# SF32LB55x register map
File version: 1.0
CPU: CM33 r0p1, little endian, MPU, FPU, 3 interrupt priority bits
Registers are 32-bit, read-write, reset 0x0 unless marked. A register's access mark holds for its fields unless they carry their own. Offsets are from the block's base; [hi:lo] are bit positions; {n}, {i} and the like mark numbered series.

## SDADC
Base 0x40057000
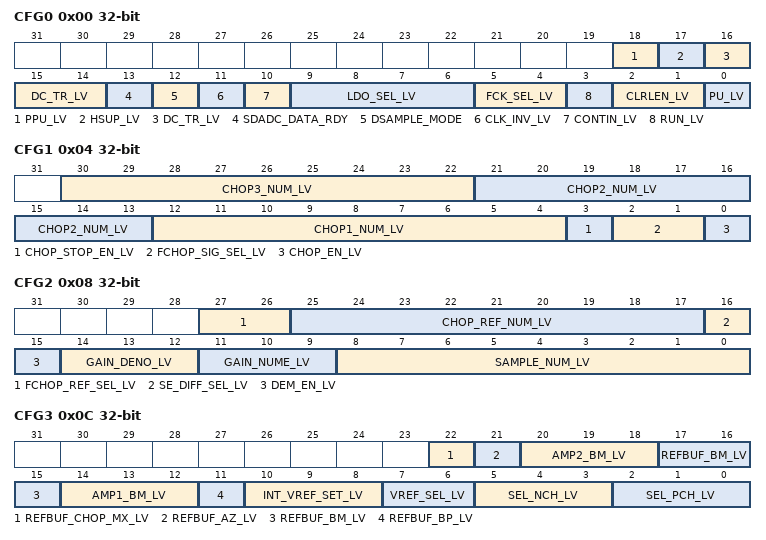
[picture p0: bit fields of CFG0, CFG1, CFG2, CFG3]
0x00 CFG0
  [18] PPU_LV — reference generate pre-power-up
  [17] HSUP_LV — supply votage 0x0:1.8v 0x1: 3.3v
  [16:14] DC_TR_LV — DCTR
  [13] SDADC_DATA_RDY — 1 indicates sample adc data done once
  [12] DSAMPLE_MODE — 1: sample adc data on a maximum of five channels in non-contious mode; 0: sample adc data on only one channel in non-contious mode
  [11] CLK_INV_LV — inverse clk to folter or not 0x0:no 0x1:yes
  [10] CONTIN_LV — continous sample or not 0x0:no 0x1:yes
  [9:6] LDO_SEL_LV — ldo voltage selection
  [5:4] FCK_SEL_LV — ADC clock dividing selection
  [3] RUN_LV — start sdadc sample in continous mode
  [2:1] CLRLEN_LV — length of clear pulse
  [0] PU_LV — power up
0x04 CFG1
  [30:22] CHOP3_NUM_LV — chopping weight controlling of 3rd stage
  [21:13] CHOP2_NUM_LV — chopping weight controlling of 2nd stage
  [12:4] CHOP1_NUM_LV — chopping weight controlling of 1st stage
  [3] CHOP_STOP_EN_LV — chopping weight controlling enable
  [2:1] FCHOP_SIG_SEL_LV — siganal path chopping frequency
  [0] CHOP_EN_LV — chopping enable
0x08 CFG2
  [27:26] FCHOP_REF_SEL_LV — reference buffer chopping frequency
  [25:17] CHOP_REF_NUM_LV — chopping weight controlling of reference buffer
  [16] SE_DIFF_SEL_LV — single ended or differencial input 0x0: single end 0x1:differencial
  [15] DEM_EN_LV — DEM enable of gain controlling circuits
  [14:12] GAIN_DENO_LV — denominator of gain
  [11:9] GAIN_NUME_LV — numerator of gain
  [8:0] SAMPLE_NUM_LV — number of sample
0x0C CFG3
  [22] REFBUF_CHOP_MX_LV — reference buffer chopping mixed with dout 0x0: no 0x1:yes
  [21] REFBUF_AZ_LV — reference buffer autozero 0x0: no 0x1: yes
  [20:18] AMP2_BM_LV — bias mode of 2nd and 3rd opamp
  [17:15] REFBUF_BM_LV — bias mode of reference buffer
  [14:12] AMP1_BM_LV — bias mode of first opamp
  [11] REFBUF_BP_LV — reference buffer bypass 0x0: no 0x1:yes
  [10:8] INT_VREF_SET_LV — set internal reference voltage
  [7:6] VREF_SEL_LV — reference source selection
  [5:3] SEL_NCH_LV — Select N-side input channel for SDMADC, 0 for channel 0 , 4 for channel 4
  [2:0] SEL_PCH_LV — Select P-side input channel for SDMADC, 0 for channel 0 , 4 for channel 4
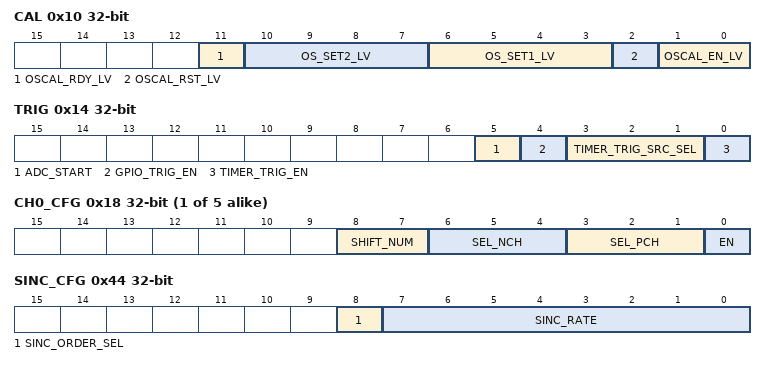
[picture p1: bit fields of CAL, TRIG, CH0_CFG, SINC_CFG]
0x10 CAL
  [11] OSCAL_RDY_LV — 1 indicates calibration done once
  [10:7] OS_SET2_LV — offset code for rebuf
  [6:3] OS_SET1_LV — offset code for 1st opamp
  [2] OSCAL_RST_LV — reset for offset calibration 0x0: reset 0x1: release
  [1:0] OSCAL_EN_LV — offset calibration enable 0x0: no 0x1: 1st opamp 0x2: rebuffer 0x3: 2nd opamp 0x4:3rd opamp
0x14 TRIG
  [5] ADC_START — trigger sdadc sample in non-continous mode once
  [4] GPIO_TRIG_EN — enable gpio postive edge to trigger sdadc sample in non-continous mode
  [3:1] TIMER_TRIG_SRC_SEL — timer trigger source select
  [0] TIMER_TRIG_EN — enable timer trigger source select
{0x18+4i} CH{i}_CFG (i=0..4)
  [8:7] SHIFT_NUM — channel {i} sample times (= 2^shift_num)
  [6:4] SEL_NCH — channel {i} selection N-side input
  [3:1] SEL_PCH — channel {i} selection P-side input
  [0] EN — enable channel {i} sample
{0x2C+4i} CH{i}_DOUT (i=0..4)
  [23:0] DATA — channel {i} average value
0x40 SINGLE_DOUT
  [23:0] DATA — sample date when contin_lv is 0 and dsample_mode is 0
0x44 SINC_CFG
  [8] SINC_ORDER_SEL — 1:select four differentiators in sinc filter; 0:select three differentiators in sinc filter
  [7:0] SINC_RATE — dowmsampling rate of sinc filter
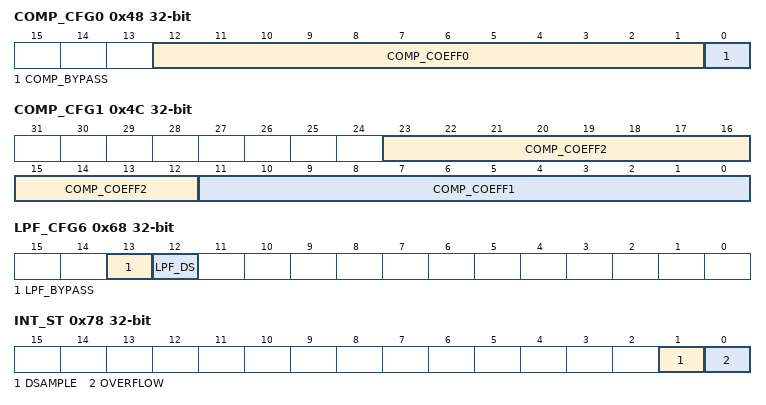
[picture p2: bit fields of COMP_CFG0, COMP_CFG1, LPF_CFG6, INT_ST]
0x48 COMP_CFG0
  [12:1] COMP_COEFF0 — coefficient 0 of compensating filter
  [0] COMP_BYPASS — 1: bypass compensating filter ; 0: enable compensating filter
0x4C COMP_CFG1
  [23:12] COMP_COEFF2 — coefficient 2 of compensating filter
  [11:0] COMP_COEFF1 — coefficient 1 of compensating filter
0x68 LPF_CFG6
  [13] LPF_BYPASS — 1:bypass low-pass filter ; 0: enable low-pass filter
  [12] LPF_DS — 1:downsampling rate of low pass filter is two;0:No downsampling of low pass filter
0x6C DMA_CFG
  [0] RX_DMA_MSK — 1:disable sdadc dma request; 0: enable sdadc dma request
0x74 FIFO_ST
  [0] EMPTY — 1 indicates sdadc fifo is empty
0x78 INT_ST
  [1] DSAMPLE — 1 indicates sdadc sample done in non-continous mode and as one of irq source at same time
  [0] OVERFLOW — 1 indicates sdadc fifo has already overflowed and as one of irq source at same time
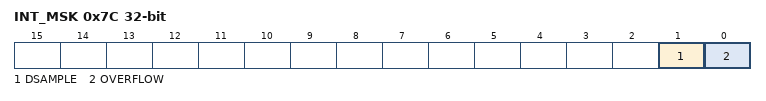
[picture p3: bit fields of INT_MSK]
0x7C INT_MSK
  [1] DSAMPLE — 1:disable sdadc sample done irq to system; 0: enable sdadc sample done irq to system
  [0] OVERFLOW — 1:disable sdadc fifo overflow irq to system; 0: enable sdadc fifo overflow irq to system
0x80 INT_CLR
  [0] INT_CLR — clear sdadc irq
0x84 FSM_ST
  [0] ACTIVE — 1 indicates sdadc non-continous mode is running
